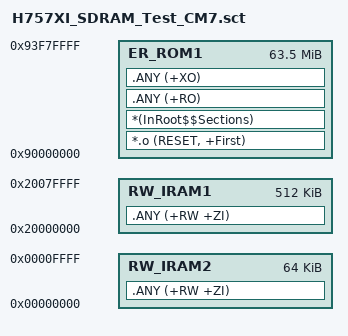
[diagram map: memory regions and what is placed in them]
; *************************************************************
; *** Scatter-Loading Description File generated by uVision ***
; *************************************************************

LR_ROM1 0x90000000 0x03F80000  {    ; load region size_region
  ER_ROM1 0x90000000 0x03F80000  {  ; load address = execution address
   *.o (RESET, +First)
   *(InRoot$$Sections)
   .ANY (+RO)
   .ANY (+XO)
  }
  RW_IRAM1 0x20000000 0x00080000  {  ; RW data
   .ANY (+RW +ZI)
  }
  RW_IRAM2 0x00000000 0x00010000  {
   .ANY (+RW +ZI)
  }
}

